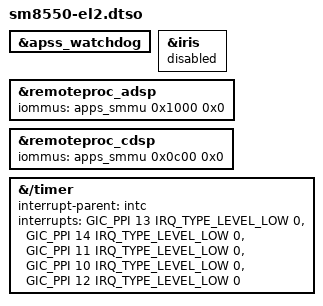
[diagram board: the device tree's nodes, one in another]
// SPDX-License-Identifier: BSD-3-Clause
/*
 * Copyright (c) Qualcomm Technologies, Inc. and/or its subsidiaries.
 *
 * SM8550 specific modifications required to boot in EL2.
 */

/dts-v1/;
/plugin/;

#include <dt-bindings/interrupt-controller/arm-gic.h>

&apss_watchdog {
	status = "okay";
};

&iris {
	/* TODO: Add video-firmware iommus to start IRIS from EL2 */
	status = "disabled";
};

/*
 * At EL2 Linux owns the APPS SMMU, which blocks unknown streams: describe the
 * DSP streams the hypervisor maps otherwise, so that the PAS driver maps the
 * DSP carve-outs for them.
 */
&remoteproc_adsp {
	iommus = <&apps_smmu 0x1000 0x0>;
};

&remoteproc_cdsp {
	iommus = <&apps_smmu 0x0c00 0x0>;
};

/*
 * The cores implement the EL2 virtual timer (PPI 12), which Linux uses when it
 * runs at EL2 with VHE; without it Linux falls back to the EL2 physical timer.
 */
&{/timer} {
	interrupt-parent = <&intc>;
	interrupts = <GIC_PPI 13 IRQ_TYPE_LEVEL_LOW 0>,
		     <GIC_PPI 14 IRQ_TYPE_LEVEL_LOW 0>,
		     <GIC_PPI 11 IRQ_TYPE_LEVEL_LOW 0>,
		     <GIC_PPI 10 IRQ_TYPE_LEVEL_LOW 0>,
		     <GIC_PPI 12 IRQ_TYPE_LEVEL_LOW 0>;
};
